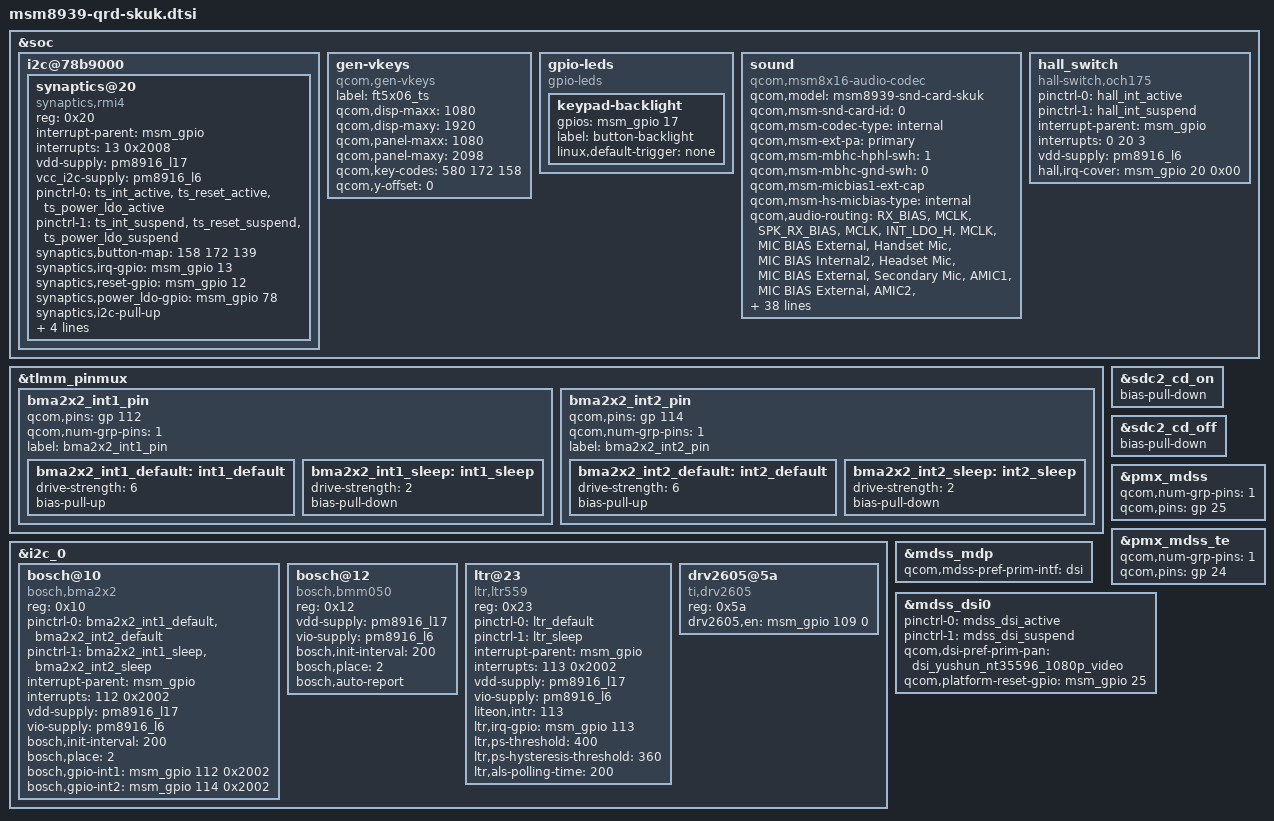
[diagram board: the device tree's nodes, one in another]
/* Copyright (c) 2014-2015, The Linux Foundation. All rights reserved.
 *
 * This program is free software; you can redistribute it and/or modify
 * it under the terms of the GNU General Public License version 2 and
 * only version 2 as published by the Free Software Foundation.
 *
 * This program is distributed in the hope that it will be useful,
 * but WITHOUT ANY WARRANTY; without even the implied warranty of
 * MERCHANTABILITY or FITNESS FOR A PARTICULAR PURPOSE.  See the
 * GNU General Public License for more details.
 */

#include "msm8939-qrd.dtsi"
#include "dsi-panel-r63315-1080p-video.dtsi"
#include "dsi-panel-yushun-nt35596-1080p-video.dtsi"
#include "msm8939-camera-sensor-qrd.dtsi"
#include "dsi-panel-nt35596-1080p-video.dtsi"
#include "dsi-panel-truly-r63315-new-1080p-video.dtsi"
&soc {
	i2c@78b9000 { /* BLSP1 QUP5 */
		synaptics@20 {
			compatible = "synaptics,rmi4";
			reg = <0x20>;
			interrupt-parent = <&msm_gpio>;
			interrupts = <13 0x2008>;
			vdd-supply = <&pm8916_l17>;
            vcc_i2c-supply = <&pm8916_l6>;
			/* pins used by touchscreen */
			pinctrl-names = "pmx_ts_active","pmx_ts_suspend";
			pinctrl-0 = <&ts_int_active &ts_reset_active &ts_power_ldo_active>;
            pinctrl-1 = <&ts_int_suspend &ts_reset_suspend &ts_power_ldo_suspend>;
            synaptics,button-map= <158 172 139>;
			synaptics,irq-gpio = <&msm_gpio 13 0x2008>;
			synaptics,reset-gpio = <&msm_gpio 12 0x0>;
			synaptics,power_ldo-gpio = <&msm_gpio 78 0x0>;
			//synaptics,fw-image-name = "synaptics_dsx_fw_update.bin";
			synaptics,i2c-pull-up;
			synaptics,power-down;
			synaptics,disable-gpios;
			synaptics,display-coords = <0 0 1079 1919>;
			synaptics,panel-coords = <0 0 1079 2084>;
		};
	};

	gen-vkeys {
		compatible = "qcom,gen-vkeys";
		label = "ft5x06_ts";
		qcom,disp-maxx = <1080>;
		qcom,disp-maxy = <1920>;
		qcom,panel-maxx = <1080>;
		qcom,panel-maxy = <2098>;
		qcom,key-codes = <580 172 158>;
		qcom,y-offset = <0>;
	};
	gpio-leds {
                compatible = "gpio-leds";
                status = "okay";
                pinctrl-names = "default";
                keypad-backlight {
                        gpios = <&msm_gpio 17 0>;
                        label = "button-backlight";
                        linux,default-trigger = "none";
                };
	};

	sound {
		compatible = "qcom,msm8x16-audio-codec";
		qcom,model = "msm8939-snd-card-skuk";
		qcom,msm-snd-card-id = <0>;
		qcom,msm-codec-type = "internal";
		qcom,msm-ext-pa = "primary";
		qcom,msm-mbhc-hphl-swh = <1>;
		qcom,msm-mbhc-gnd-swh = <0>;
		qcom,msm-micbias1-ext-cap;
		qcom,msm-hs-micbias-type = "internal";
		qcom,audio-routing =
			"RX_BIAS", "MCLK",
			"SPK_RX_BIAS", "MCLK",
			"INT_LDO_H", "MCLK",
			"MIC BIAS External", "Handset Mic",
			"MIC BIAS Internal2", "Headset Mic",
			"MIC BIAS External", "Secondary Mic",
			"AMIC1", "MIC BIAS External",
			"AMIC2", "MIC BIAS Internal2",
			"AMIC3", "MIC BIAS External";
		pinctrl-names = "cdc_lines_act",
				"cdc_lines_sus";
		pinctrl-0 = <&cdc_pdm_lines_act>;
		pinctrl-1 = <&cdc_pdm_lines_sus>;
		asoc-platform = <&pcm0>, <&pcm1>, <&voip>, <&voice>,
				<&loopback>, <&compress>, <&hostless>,
				<&afe>, <&lsm>, <&routing>, <&lpa>;
		asoc-platform-names = "msm-pcm-dsp.0", "msm-pcm-dsp.1",
				"msm-voip-dsp", "msm-pcm-voice", "msm-pcm-loopback",
				"msm-compress-dsp", "msm-pcm-hostless", "msm-pcm-afe",
				"msm-lsm-client", "msm-pcm-routing", "msm-pcm-lpa";
		asoc-cpu = <&dai_pri_auxpcm>, <&dai_hdmi>, <&dai_mi2s0>, <&dai_mi2s1>,
				<&dai_mi2s2>, <&dai_mi2s3>, <&sb_0_rx>, <&sb_0_tx>,
				<&sb_1_rx>, <&sb_1_tx>, <&sb_3_rx>, <&sb_3_tx>,
				<&sb_4_rx>, <&sb_4_tx>, <&sb_5_tx>, <&bt_sco_rx>,
				<&bt_sco_tx>, <&bt_a2dp_rx>,
				<&int_fm_rx>, <&int_fm_tx>, <&afe_pcm_rx>,
				<&afe_pcm_tx>, <&afe_proxy_rx>, <&afe_proxy_tx>,
				<&incall_record_rx>, <&incall_record_tx>, <&incall_music_rx>,
				<&incall_music_2_rx>;
		asoc-cpu-names = "msm-dai-q6-auxpcm.1", "msm-dai-q6-hdmi.8", "msm-dai-q6-mi2s.0",
				"msm-dai-q6-mi2s.1", "msm-dai-q6-mi2s.2",
				"msm-dai-q6-mi2s.3", "msm-dai-q6-dev.16384",
				"msm-dai-q6-dev.16385", "msm-dai-q6-dev.16386",
				"msm-dai-q6-dev.16387", "msm-dai-q6-dev.16390",
				"msm-dai-q6-dev.16391", "msm-dai-q6-dev.16392",
				"msm-dai-q6-dev.16393", "msm-dai-q6-dev.16395",
				"msm-dai-q6-dev.12288", "msm-dai-q6-dev.12289",
				"msm-dai-q6-dev.12290", "msm-dai-q6-dev.12292",
				"msm-dai-q6-dev.12293",	"msm-dai-q6-dev.224",
				"msm-dai-q6-dev.225", "msm-dai-q6-dev.241",
				"msm-dai-q6-dev.240", "msm-dai-q6-dev.32771",
				"msm-dai-q6-dev.32772", "msm-dai-q6-dev.32773",
				"msm-dai-q6-dev.32770";
		asoc-codec = <&stub_codec>, <&pm8916_tombak_dig>;
		asoc-codec-names = "msm-stub-codec.1", "tombak_codec";
	};

       hall_switch {
		compatible = "hall-switch,och175";
		pinctrl-names = "hall_active","hall_suspend";
		pinctrl-0 = <&hall_int_active>;
		pinctrl-1 = <&hall_int_suspend>;
		interrupt-parent = <&msm_gpio>;
		interrupts = <0 20 3>;
		vdd-supply = <&pm8916_l6>;
		interrupt-names = "hall_irq";
		hall,irq-cover = <&msm_gpio 20 0x00>;
	};
};


&tlmm_pinmux {
	bma2x2_int1_pin {
		qcom,pins = <&gp 112>;
		qcom,num-grp-pins = <1>;
		label = "bma2x2_int1_pin";
		bma2x2_int1_default: int1_default {
			  drive-strength = <6>;
			  bias-pull-up;
		};
		bma2x2_int1_sleep: int1_sleep {
			  drive-strength = <2>;
			  bias-pull-down;
		};
	};

	bma2x2_int2_pin {
		qcom,pins = <&gp 114>;
		qcom,num-grp-pins = <1>;
		label = "bma2x2_int2_pin";
		bma2x2_int2_default: int2_default {
			  drive-strength = <6>;
			  bias-pull-up;
		};
		bma2x2_int2_sleep: int2_sleep {
			  drive-strength = <2>;
			  bias-pull-down;
		};
	};
};

&i2c_0 { /* BLSP1 QUP2 */
	bosch@10 { /* Accelerometer sensor */
		compatible = "bosch,bma2x2";
		reg = <0x10>;
		pinctrl-names = "bma_default","bma_sleep";
		pinctrl-0 = <&bma2x2_int1_default &bma2x2_int2_default>;
		pinctrl-1 = <&bma2x2_int1_sleep &bma2x2_int2_sleep>;
		interrupt-parent = <&msm_gpio>;
		interrupts = <112 0x2002>;
		vdd-supply = <&pm8916_l17>;
		vio-supply = <&pm8916_l6>;
		bosch,init-interval = <200>;
		bosch,place = <2>;
		bosch,gpio-int1 = <&msm_gpio 112 0x2002>;
		bosch,gpio-int2 = <&msm_gpio 114 0x2002>;
	};
    
	bosch@12 { /* magnetic sensor */
		compatible = "bosch,bmm050";
		reg = <0x12>;
		vdd-supply = <&pm8916_l17>;
		vio-supply = <&pm8916_l6>;
		bosch,init-interval = <200>;
		bosch,place = <2>;
		bosch,auto-report;
	};

	ltr@23 { /* Ambient light and proximity sensor */
		compatible = "ltr,ltr559";
		reg = <0x23>;
		pinctrl-names = "default","sleep";
		pinctrl-0 = <&ltr_default>;
		pinctrl-1 = <&ltr_sleep>;
		interrupt-parent = <&msm_gpio>;
		interrupts = <113 0x2002>;
		vdd-supply = <&pm8916_l17>;
		vio-supply = <&pm8916_l6>;
		liteon,intr = <113>;
		ltr,irq-gpio = <&msm_gpio 113 0x2002>;
		ltr,ps-threshold = <400>;
		ltr,ps-hysteresis-threshold = <360>;
		ltr,als-polling-time = <200>;
	};

	drv2605@5a {/* moto ic */
		compatible = "ti,drv2605";
		reg = <0x5a>;
		drv2605,en= <&msm_gpio 109 0>;
	};
};

&sdc2_cd_on {
	/delete-property/ bias-pull-up;
	bias-pull-down;
};

&sdc2_cd_off {
	/delete-property/ bias-disable;
	bias-pull-down;
};

&mdss_mdp {
	qcom,mdss-pref-prim-intf = "dsi";
};

&pmx_mdss {
	qcom,num-grp-pins = <1>;
	qcom,pins = <&gp 25>;
};

&pmx_mdss_te {
        qcom,num-grp-pins = <1>;
        qcom,pins = <&gp 24>;
};

&mdss_dsi0 {
	pinctrl-names = "mdss_default", "mdss_sleep";
	pinctrl-0 = <&mdss_dsi_active>;
	pinctrl-1 = <&mdss_dsi_suspend>;
	qcom,dsi-pref-prim-pan = <&dsi_yushun_nt35596_1080p_video>;

	qcom,platform-reset-gpio = <&msm_gpio 25 0>;
};

